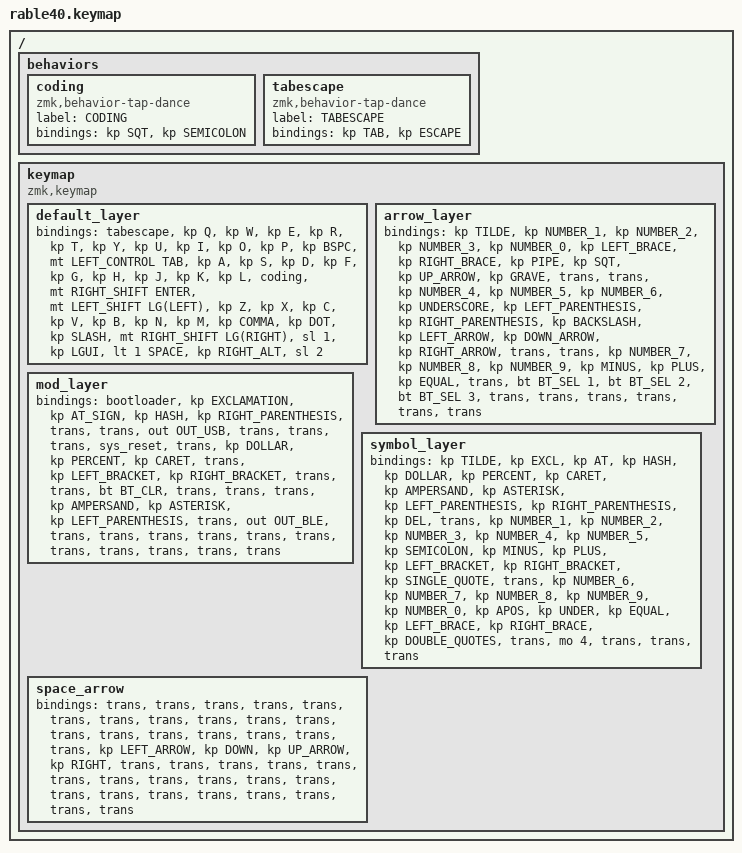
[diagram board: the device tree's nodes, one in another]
/*
 * Copyright (c) 2021 Nick Winans
 *
 * SPDX-License-Identifier: MIT
 */

#include <behaviors.dtsi>
#include <dt-bindings/zmk/bt.h>
#include <dt-bindings/zmk/keys.h>
#include <dt-bindings/zmk/outputs.h>

/ {
    behaviors {
        coding: coding {
            compatible = "zmk,behavior-tap-dance";
            label = "CODING";
            #binding-cells = <0>;
            bindings =
                <&kp SQT>,
                <&kp SEMICOLON>;
        };
        tabescape: tabescape {
            compatible = "zmk,behavior-tap-dance";
            label = "TABESCAPE";
            #binding-cells = <0>;
            bindings =
                <&kp TAB>,
                <&kp ESCAPE>;
        };
    };

    keymap {
        compatible = "zmk,keymap";

        default_layer {
            bindings = <
&tabescape  &kp Q  &kp W  &kp E  &kp R  &kp T  &kp Y  &kp U  &kp I  &kp O  &kp P  &kp BSPC  &mt LEFT_CONTROL TAB  &kp A  &kp S  &kp D  &kp F  &kp G  &kp H  &kp J  &kp K  &kp L  &coding  &mt RIGHT_SHIFT ENTER  &mt LEFT_SHIFT LG(LEFT)  &kp Z  &kp X  &kp C  &kp V  &kp B  &kp N  &kp M  &kp COMMA  &kp DOT  &kp SLASH  &mt RIGHT_SHIFT LG(RIGHT)  &sl 1  &kp LGUI  &lt 1 SPACE  &kp RIGHT_ALT  &sl 2
            >;
        };

        arrow_layer {
            bindings = <
&kp TILDE  &kp NUMBER_1  &kp NUMBER_2  &kp NUMBER_3  &kp NUMBER_0  &kp LEFT_BRACE  &kp RIGHT_BRACE  &kp PIPE  &kp SQT  &kp UP_ARROW  &kp GRAVE  &trans  &trans  &kp NUMBER_4  &kp NUMBER_5  &kp NUMBER_6  &kp UNDERSCORE  &kp LEFT_PARENTHESIS  &kp RIGHT_PARENTHESIS  &kp BACKSLASH  &kp LEFT_ARROW  &kp DOWN_ARROW  &kp RIGHT_ARROW  &trans  &trans  &kp NUMBER_7  &kp NUMBER_8  &kp NUMBER_9  &kp MINUS  &kp PLUS  &kp EQUAL  &trans  &bt BT_SEL 1  &bt BT_SEL 2  &bt BT_SEL 3  &trans  &trans  &trans  &trans  &trans  &trans
            >;
        };

        mod_layer {
            bindings = <
&bootloader  &kp EXCLAMATION  &kp AT_SIGN  &kp HASH  &kp RIGHT_PARENTHESIS  &trans  &trans  &out OUT_USB  &trans  &trans  &trans  &sys_reset  &trans  &kp DOLLAR  &kp PERCENT  &kp CARET  &trans  &kp LEFT_BRACKET  &kp RIGHT_BRACKET  &trans  &trans  &bt BT_CLR  &trans  &trans  &trans  &kp AMPERSAND  &kp ASTERISK  &kp LEFT_PARENTHESIS  &trans  &out OUT_BLE  &trans  &trans  &trans  &trans  &trans  &trans  &trans  &trans  &trans  &trans  &trans
            >;
        };

        symbol_layer {
            bindings = <
&kp TILDE  &kp EXCL  &kp AT  &kp HASH  &kp DOLLAR  &kp PERCENT  &kp CARET  &kp AMPERSAND  &kp ASTERISK  &kp LEFT_PARENTHESIS  &kp RIGHT_PARENTHESIS  &kp DEL  &trans  &kp NUMBER_1  &kp NUMBER_2  &kp NUMBER_3  &kp NUMBER_4  &kp NUMBER_5  &kp SEMICOLON  &kp MINUS  &kp PLUS  &kp LEFT_BRACKET  &kp RIGHT_BRACKET  &kp SINGLE_QUOTE  &trans  &kp NUMBER_6  &kp NUMBER_7  &kp NUMBER_8  &kp NUMBER_9  &kp NUMBER_0  &kp APOS  &kp UNDER  &kp EQUAL  &kp LEFT_BRACE  &kp RIGHT_BRACE  &kp DOUBLE_QUOTES  &trans  &mo 4  &trans  &trans  &trans
            >;
        };

        space_arrow {
            bindings = <
&trans  &trans  &trans  &trans  &trans  &trans  &trans  &trans  &trans  &trans  &trans  &trans  &trans  &trans  &trans  &trans  &trans  &trans  &kp LEFT_ARROW  &kp DOWN  &kp UP_ARROW  &kp RIGHT  &trans  &trans  &trans  &trans  &trans  &trans  &trans  &trans  &trans  &trans  &trans  &trans  &trans  &trans  &trans  &trans  &trans  &trans  &trans
            >;
        };
    };
};
